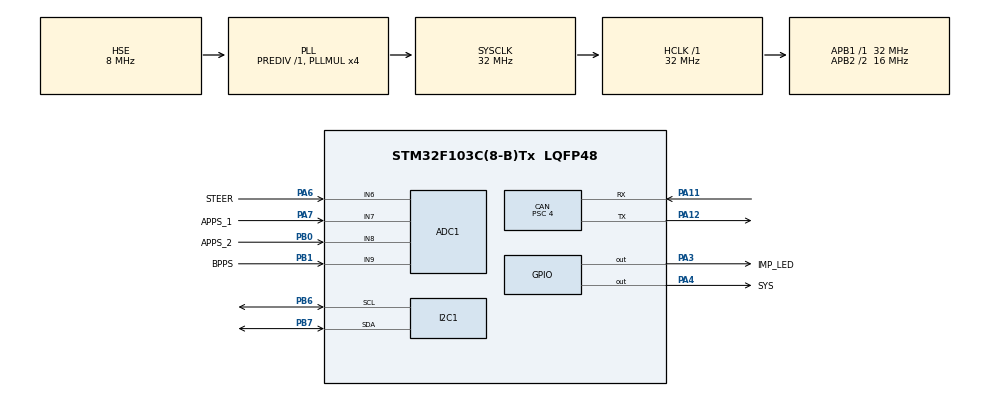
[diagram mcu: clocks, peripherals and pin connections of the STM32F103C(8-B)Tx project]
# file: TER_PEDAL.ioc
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ADC1.Channel-0\#ChannelRegularConversion=ADC_CHANNEL_6
ADC1.Channel-1\#ChannelRegularConversion=ADC_CHANNEL_7
ADC1.Channel-2\#ChannelRegularConversion=ADC_CHANNEL_8
ADC1.Channel-4\#ChannelRegularConversion=ADC_CHANNEL_9
ADC1.ContinuousConvMode=ENABLE
ADC1.NbrOfConversion=4
ADC1.NbrOfConversionFlag=1
ADC1.Rank-0\#ChannelRegularConversion=1
ADC1.Rank-1\#ChannelRegularConversion=2
ADC1.Rank-2\#ChannelRegularConversion=3
ADC1.Rank-4\#ChannelRegularConversion=4
ADC1.SamplingTime-0\#ChannelRegularConversion=ADC_SAMPLETIME_1CYCLE_5
ADC1.SamplingTime-1\#ChannelRegularConversion=ADC_SAMPLETIME_1CYCLE_5
ADC1.SamplingTime-2\#ChannelRegularConversion=ADC_SAMPLETIME_1CYCLE_5
ADC1.SamplingTime-4\#ChannelRegularConversion=ADC_SAMPLETIME_1CYCLE_5
ADC1.master=1
CAN.ABOM=ENABLE
CAN.AWUM=DISABLE
CAN.BS1=CAN_BS1_6TQ
CAN.BS2=CAN_BS2_1TQ
CAN.CalculateBaudRate=1000000
CAN.CalculateTimeBit=1000
CAN.CalculateTimeQuantum=125.0
CAN.Mode=CAN_MODE_NORMAL
CAN.Prescaler=4
CAN.SJW=CAN_SJW_2TQ
Dma.ADC1.0.Direction=DMA_PERIPH_TO_MEMORY
Dma.ADC1.0.Instance=DMA1_Channel1
Dma.ADC1.0.MemDataAlignment=DMA_MDATAALIGN_WORD
Dma.ADC1.0.MemInc=DMA_MINC_ENABLE
Dma.ADC1.0.Mode=DMA_CIRCULAR
Dma.ADC1.0.PeriphDataAlignment=DMA_PDATAALIGN_WORD
Dma.ADC1.0.PeriphInc=DMA_PINC_DISABLE
Dma.ADC1.0.Priority=DMA_PRIORITY_LOW
Dma.Request0=ADC1
I2C1.I2C_Mode=I2C_Fast
Mcu.Family=STM32F1
Mcu.Name=STM32F103C(8-B)Tx
Mcu.Package=LQFP48
NVIC.PriorityGroup=NVIC_PRIORITYGROUP_4
NVIC.TIM2_IRQn=true\:1\:0\:true\:false\:true\:true\:true\:true
NVIC.USB_LP_CAN1_RX0_IRQn=true\:1\:0\:true\:true\:true\:1\:true\:true\:true
PA11.Mode=CAN_Activate
PA11.Signal=CAN_RX
PA12.Mode=CAN_Activate
PA12.Signal=CAN_TX
PA13.Mode=Serial_Wire
PA13.Signal=SYS_JTMS-SWDIO
PA14.Mode=Serial_Wire
PA14.Signal=SYS_JTCK-SWCLK
PA3.GPIO_Label=IMP_LED
PA3.Signal=GPIO_Output
PA4.GPIO_Label=SYS
PA4.Signal=GPIO_Output
PA6.GPIO_Label=STEER
PA6.Signal=ADCx_IN6
PA7.GPIO_Label=APPS_1
PA7.Signal=ADCx_IN7
PB0.GPIO_Label=APPS_2
PB0.Signal=ADCx_IN8
PB1.GPIO_Label=BPPS
PB1.Signal=ADCx_IN9
PB6.Mode=I2C
PB6.Signal=I2C1_SCL
PB7.Mode=I2C
PB7.Signal=I2C1_SDA
PD0-OSC_IN.Mode=HSE-External-Oscillator
PD0-OSC_IN.Signal=RCC_OSC_IN
PD1-OSC_OUT.Mode=HSE-External-Oscillator
PD1-OSC_OUT.Signal=RCC_OSC_OUT
ProjectManager.HeapSize=0x200
ProjectManager.StackSize=0x400
ProjectManager.TargetToolchain=STM32CubeIDE
RCC.ADCPresc=RCC_ADCPCLK2_DIV4
RCC.AHBFreq_Value=32000000
RCC.APB1Freq_Value=32000000
RCC.APB1TimFreq_Value=32000000
RCC.APB2CLKDivider=RCC_HCLK_DIV2
RCC.APB2Freq_Value=16000000
RCC.APB2TimFreq_Value=32000000
RCC.HCLKFreq_Value=32000000
RCC.PLLMUL=RCC_PLL_MUL4
RCC.PLLSourceVirtual=RCC_PLLSOURCE_HSE
RCC.SYSCLKFreq_VALUE=32000000
RCC.SYSCLKSource=RCC_SYSCLKSOURCE_PLLCLK
RCC.USBFreq_Value=32000000
SH.ADCx_IN6.0=ADC1_IN6,IN6
SH.ADCx_IN7.0=ADC1_IN7,IN7
SH.ADCx_IN8.0=ADC1_IN8,IN8
SH.ADCx_IN9.0=ADC1_IN9,IN9
TIM2.Period=63999
TIM2.Prescaler=0
VP_TIM2_VS_ClockSourceINT.Mode=Internal
board=custom

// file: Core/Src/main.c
/* USER CODE BEGIN Header */
/**
 ******************************************************************************
 * @file           : main.c
 * @brief          : Main program body
 ******************************************************************************
 * @attention
 *
 * Copyright (c) 2023 STMicroelectronics.
 * All rights reserved.
 *
 * This software is licensed under terms that can be found in the LICENSE file
 * in the root directory of this software component.
 * If no LICENSE file comes with this software, it is provided AS-IS.
 *
 ******************************************************************************
 */
/* USER CODE END Header */
#include "main.h"
#include "adc.h"
#include "can.h"
#include "dma.h"
#include "i2c.h"
#include "tim.h"
#include "gpio.h"

/* USER CODE BEGIN Includes */
#include "TeR_CAN.h" //Master libray
#include "pedal.h" //Board functions Library
/* USER CODE END Includes */

/* USER CODE BEGIN PV */
EE24_HandleTypeDef ee24;

//Mensajes

/* USER CODE END PV */

void SystemClock_Config(void);
static void MX_NVIC_Init(void);
/* USER CODE BEGIN PFP */
void readSensors(void); //Lectura de todos los sensores

/* USER CODE END PFP */

int main(void) {

	/* MCU Configuration--------------------------------------------------------*/

	/* Reset of all peripherals, Initializes the Flash interface and the Systick. */
	HAL_Init();

	/* Configure the system clock */
	SystemClock_Config();

	/* Initialize all configured peripherals */
	MX_GPIO_Init();
	MX_DMA_Init();
	MX_ADC1_Init();
	MX_CAN_Init();
	MX_TIM2_Init();
	MX_I2C1_Init();

	/* Initialize interrupts */
	MX_NVIC_Init();
	/* USER CODE BEGIN 2 */
	EE24_Init(&ee24, &hi2c1, EE24_ADDRESS_DEFAULT);
	initPedal(&hadc1); //Carga los offsets en la placa y arranca enganchada al adc1
	initCAN(&hcan, &htim2); //Arranca el can enganchado a el timer 2
	/* USER CODE END 2 */

	/* Infinite loop */
	/* USER CODE BEGIN WHILE */
	while (1) {
		; //Good code depends just on interruptions : )
		/* USER CODE END WHILE */

	}
}

void SystemClock_Config(void) {
	RCC_OscInitTypeDef RCC_OscInitStruct = { 0 };
	RCC_ClkInitTypeDef RCC_ClkInitStruct = { 0 };
	RCC_PeriphCLKInitTypeDef PeriphClkInit = { 0 };

	/** Initializes the RCC Oscillators according to the specified parameters
	 * in the RCC_OscInitTypeDef structure.
	 */
	RCC_OscInitStruct.OscillatorType = RCC_OSCILLATORTYPE_HSE;
	RCC_OscInitStruct.HSEState = RCC_HSE_ON;
	RCC_OscInitStruct.HSEPredivValue = RCC_HSE_PREDIV_DIV1;
	RCC_OscInitStruct.HSIState = RCC_HSI_ON;
	RCC_OscInitStruct.PLL.PLLState = RCC_PLL_ON;
	RCC_OscInitStruct.PLL.PLLSource = RCC_PLLSOURCE_HSE;
	RCC_OscInitStruct.PLL.PLLMUL = RCC_PLL_MUL4;
	if (HAL_RCC_OscConfig(&RCC_OscInitStruct) != HAL_OK) {
		Error_Handler();
	}

	/** Initializes the CPU, AHB and APB buses clocks
	 */
	RCC_ClkInitStruct.ClockType = RCC_CLOCKTYPE_HCLK | RCC_CLOCKTYPE_SYSCLK
			| RCC_CLOCKTYPE_PCLK1 | RCC_CLOCKTYPE_PCLK2;
	RCC_ClkInitStruct.SYSCLKSource = RCC_SYSCLKSOURCE_PLLCLK;
	RCC_ClkInitStruct.AHBCLKDivider = RCC_SYSCLK_DIV1;
	RCC_ClkInitStruct.APB1CLKDivider = RCC_HCLK_DIV1;
	RCC_ClkInitStruct.APB2CLKDivider = RCC_HCLK_DIV2;

	if (HAL_RCC_ClockConfig(&RCC_ClkInitStruct, FLASH_LATENCY_1) != HAL_OK) {
		Error_Handler();
	}
	PeriphClkInit.PeriphClockSelection = RCC_PERIPHCLK_ADC;
	PeriphClkInit.AdcClockSelection = RCC_ADCPCLK2_DIV4;
	if (HAL_RCCEx_PeriphCLKConfig(&PeriphClkInit) != HAL_OK) {
		Error_Handler();
	}
}

/**
 * @brief NVIC Configuration.
 * @retval None
 */
static void MX_NVIC_Init(void) {
	/* USB_LP_CAN1_RX0_IRQn interrupt configuration */
	HAL_NVIC_SetPriority(USB_LP_CAN1_RX0_IRQn, 1, 0);
	HAL_NVIC_EnableIRQ(USB_LP_CAN1_RX0_IRQn);
}

void Error_Handler(void) {
	/* USER CODE BEGIN Error_Handler_Debug */
	/* User can add his own implementation to report the HAL error return state */
	HAL_GPIO_WritePin(SYS_GPIO_Port, SYS_Pin, SET);
	__disable_irq();
	while (1) {
	}
	/* USER CODE END Error_Handler_Debug */
}
